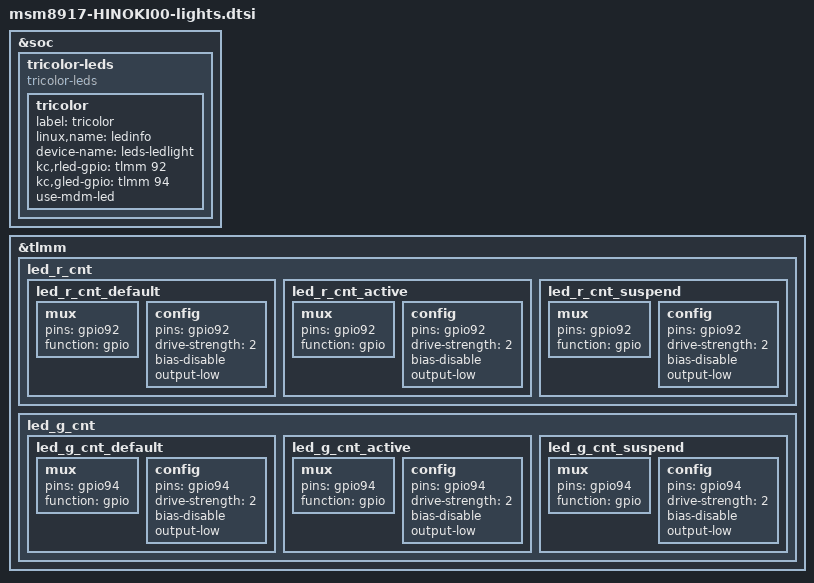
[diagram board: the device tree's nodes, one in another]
/*
 * This software is contributed or developed by KYOCERA Corporation.
 * (C) 2019 KYOCERA Corporation
 *
 * This program is free software; you can redistribute it and/or modify
 * it under the terms of the GNU General Public License version 2 and
 * only version 2 as published by the Free Software Foundation.
 *
 * This program is distributed in the hope that it will be useful,
 * but WITHOUT ANY WARRANTY; without even the implied warranty of
 * MERCHANTABILITY or FITNESS FOR A PARTICULAR PURPOSE.  See the
 * GNU General Public License for more details.
 */

&soc {
	tricolor-leds {
		compatible = "tricolor-leds";
		tricolor {
			status = "okay";
			label = "tricolor";
			linux,name = "ledinfo";
			device-name = "leds-ledlight";
			kc,rled-gpio = <&tlmm 92 0x00>;
			kc,gled-gpio = <&tlmm 94 0x00>;
			use-mdm-led;
		};
	};
};

&tlmm {

	/delete-node/ wsa-vi;
	/delete-node/ sec_mi2s_sck;

	led_r_cnt {
		led_r_cnt_default: led_r_cnt_default {
			mux {
				pins = "gpio92";
				function = "gpio";
			};
			config {
				pins = "gpio92";
				drive-strength = <2>;
				bias-disable;
				output-low;
			};
		};
		led_r_cnt_active: led_r_cnt_active {
			mux {
				pins = "gpio92";
				function = "gpio";
			};
			config {
				pins = "gpio92";
				drive-strength = <2>;
				bias-disable;
				output-low;
			};
		};
		led_r_cnt_suspend: led_r_cnt_suspend {
			mux {
				pins = "gpio92";
				function = "gpio";
			};
			config {
				pins = "gpio92";
				drive-strength = <2>;
				bias-disable;
				output-low;
			};
		};
	};

	led_g_cnt {
		led_g_cnt_default: led_g_cnt_default {
			mux {
				pins = "gpio94";
				function = "gpio";
			};
			config {
				pins = "gpio94";
				drive-strength = <2>;
				bias-disable;
				output-low;
			};
		};
		led_g_cnt_active: led_g_cnt_active {
			mux {
				pins = "gpio94";
				function = "gpio";
			};
			config {
				pins = "gpio94";
				drive-strength = <2>;
				bias-disable;
				output-low;
			};
		};
		led_g_cnt_suspend: led_g_cnt_suspend {
			mux {
				pins = "gpio94";
				function = "gpio";
			};
			config {
				pins = "gpio94";
				drive-strength = <2>;
				bias-disable;
				output-low;
			};
		};
	};
};
